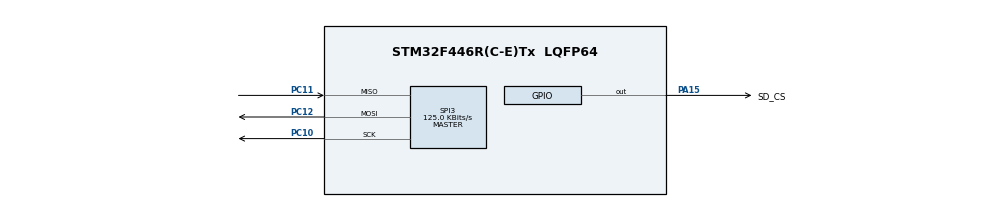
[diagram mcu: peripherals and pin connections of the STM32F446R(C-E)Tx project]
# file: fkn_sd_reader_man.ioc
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FATFS._USE_LFN=1
Mcu.Family=STM32F4
Mcu.Name=STM32F446R(C-E)Tx
Mcu.Package=LQFP64
NVIC.PriorityGroup=NVIC_PRIORITYGROUP_4
PA15.GPIO_Label=SD_CS
PA15.Signal=GPIO_Output
PC10.Mode=Full_Duplex_Master
PC10.Signal=SPI3_SCK
PC11.Mode=Full_Duplex_Master
PC11.Signal=SPI3_MISO
PC12.Mode=Full_Duplex_Master
PC12.Signal=SPI3_MOSI
ProjectManager.HeapSize=0x200
ProjectManager.StackSize=0x400
ProjectManager.TargetToolchain=STM32CubeIDE
RCC.CortexFreq_Value=16000000
RCC.USBFreq_Value=96000000
RCC.VCOOutputFreq_Value=192000000
SPI3.BaudRatePrescaler=SPI_BAUDRATEPRESCALER_128
SPI3.CalculateBaudRate=125.0 KBits/s
SPI3.Direction=SPI_DIRECTION_2LINES
SPI3.Mode=SPI_MODE_MASTER
SPI3.VirtualType=VM_MASTER
VP_FATFS_VS_Generic.Mode=User_defined
board=custom

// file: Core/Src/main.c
/* USER CODE BEGIN Header */
/**
  ******************************************************************************
  * @file           : main.c
  * @brief          : Main program body
  ******************************************************************************
  * @attention
  *
  * Copyright (c) 2023 STMicroelectronics.
  * All rights reserved.
  *
  * This software is licensed under terms that can be found in the LICENSE file
  * in the root directory of this software component.
  * If no LICENSE file comes with this software, it is provided AS-IS.
  *
  ******************************************************************************
  */
/* USER CODE END Header */
#include "main.h"
#include "fatfs.h"

/* USER CODE BEGIN Includes */
#include <stdio.h>
#include <string.h>
#include <stdarg.h> //for va_list var arg functions
/* USER CODE END Includes */

SPI_HandleTypeDef hspi3;

void SystemClock_Config(void);
static void MX_GPIO_Init(void);
static void MX_SPI3_Init(void);
/* USER CODE BEGIN PFP */
void myprintf(const char *fmt, ...);
/* USER CODE END PFP */

/* USER CODE BEGIN 0 */
void myprintf(const char *fmt, ...) {
  static char buffer[256];
  va_list args;
  va_start(args, fmt);
  vsnprintf(buffer, sizeof(buffer), fmt, args);
  va_end(args);

  int len = strlen(buffer);
  HAL_UART_Transmit(&huart2, (uint8_t*)buffer, len, -1);

}
/* USER CODE END 0 */

int main(void)
{

  /* MCU Configuration--------------------------------------------------------*/

  /* Reset of all peripherals, Initializes the Flash interface and the Systick. */
  HAL_Init();

  /* Configure the system clock */
  SystemClock_Config();

  /* Initialize all configured peripherals */
  MX_GPIO_Init();
  MX_SPI3_Init();
  MX_FATFS_Init();

  /* Infinite loop */
  while (1)
  {
//	  HAL_GPIO_TogglePin(LD2_GPIO_Port, LD2_Pin);
//	  HAL_Delay(1000);
  }
}

void SystemClock_Config(void)
{
  RCC_OscInitTypeDef RCC_OscInitStruct = {0};
  RCC_ClkInitTypeDef RCC_ClkInitStruct = {0};

  /** Configure the main internal regulator output voltage
  */
  __HAL_RCC_PWR_CLK_ENABLE();
  __HAL_PWR_VOLTAGESCALING_CONFIG(PWR_REGULATOR_VOLTAGE_SCALE3);

  /** Initializes the RCC Oscillators according to the specified parameters
  * in the RCC_OscInitTypeDef structure.
  */
  RCC_OscInitStruct.OscillatorType = RCC_OSCILLATORTYPE_HSI;
  RCC_OscInitStruct.HSIState = RCC_HSI_ON;
  RCC_OscInitStruct.HSICalibrationValue = RCC_HSICALIBRATION_DEFAULT;
  RCC_OscInitStruct.PLL.PLLState = RCC_PLL_NONE;
  if (HAL_RCC_OscConfig(&RCC_OscInitStruct) != HAL_OK)
  {
    Error_Handler();
  }

  /** Initializes the CPU, AHB and APB buses clocks
  */
  RCC_ClkInitStruct.ClockType = RCC_CLOCKTYPE_HCLK|RCC_CLOCKTYPE_SYSCLK
                              |RCC_CLOCKTYPE_PCLK1|RCC_CLOCKTYPE_PCLK2;
  RCC_ClkInitStruct.SYSCLKSource = RCC_SYSCLKSOURCE_HSI;
  RCC_ClkInitStruct.AHBCLKDivider = RCC_SYSCLK_DIV1;
  RCC_ClkInitStruct.APB1CLKDivider = RCC_HCLK_DIV1;
  RCC_ClkInitStruct.APB2CLKDivider = RCC_HCLK_DIV1;

  if (HAL_RCC_ClockConfig(&RCC_ClkInitStruct, FLASH_LATENCY_0) != HAL_OK)
  {
    Error_Handler();
  }
}

static void MX_SPI3_Init(void)
{

  /* SPI3 parameter configuration*/
  hspi3.Instance = SPI3;
  hspi3.Init.Mode = SPI_MODE_MASTER;
  hspi3.Init.Direction = SPI_DIRECTION_2LINES;
  hspi3.Init.DataSize = SPI_DATASIZE_8BIT;
  hspi3.Init.CLKPolarity = SPI_POLARITY_LOW;
  hspi3.Init.CLKPhase = SPI_PHASE_1EDGE;
  hspi3.Init.NSS = SPI_NSS_SOFT;
  hspi3.Init.BaudRatePrescaler = SPI_BAUDRATEPRESCALER_128;
  hspi3.Init.FirstBit = SPI_FIRSTBIT_MSB;
  hspi3.Init.TIMode = SPI_TIMODE_DISABLE;
  hspi3.Init.CRCCalculation = SPI_CRCCALCULATION_DISABLE;
  hspi3.Init.CRCPolynomial = 10;
  if (HAL_SPI_Init(&hspi3) != HAL_OK)
  {
    Error_Handler();
  }

}

static void MX_GPIO_Init(void)
{
  GPIO_InitTypeDef GPIO_InitStruct = {0};

  /* GPIO Ports Clock Enable */
  __HAL_RCC_GPIOA_CLK_ENABLE();
  __HAL_RCC_GPIOC_CLK_ENABLE();

  /*Configure GPIO pin Output Level */
  HAL_GPIO_WritePin(SD_CS_GPIO_Port, SD_CS_Pin, GPIO_PIN_RESET);

  /*Configure GPIO pin : SD_CS_Pin */
  GPIO_InitStruct.Pin = SD_CS_Pin;
  GPIO_InitStruct.Mode = GPIO_MODE_OUTPUT_PP;
  GPIO_InitStruct.Pull = GPIO_NOPULL;
  GPIO_InitStruct.Speed = GPIO_SPEED_FREQ_LOW;
  HAL_GPIO_Init(SD_CS_GPIO_Port, &GPIO_InitStruct);

}

void Error_Handler(void)
{
  __disable_irq();
  while (1)
  {
  }
}
